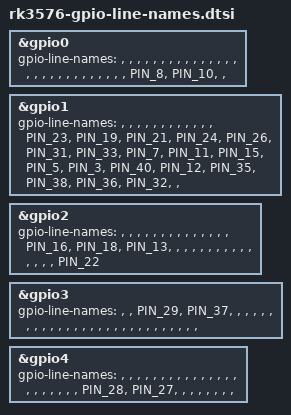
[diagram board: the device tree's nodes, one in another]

&gpio0 {
	gpio-line-names =
		/* GPIO0_A0-A3 */
		"", "", "", "",
		/* GPIO0_A4-A7 */
		"", "", "", "",

		/* GPIO0_B0-B3 */
		"", "", "", "",
		/* GPIO0_B4-B7 */
		"", "", "", "",

		/* GPIO0_C0-C3 */
		"", "", "", "",
		/* GPIO0_C4-C7 */
		"", "", "", "",

		/* GPIO0_D0-D3 */
		"", "", "", "",
		/* GPIO0_D4-D7 */
		"PIN_8", "PIN_10", "", "";
};

&gpio1 {
	gpio-line-names =
		/* GPIO1_A0-A3 */
		"", "", "", "",
		/* GPIO1_A4-A7 */
		"", "", "", "",

		/* GPIO1_B0-B3 */
		"", "", "", "",
		/* GPIO1_B4-B7 */
		"PIN_23", "PIN_19", "PIN_21", "PIN_24",

		/* GPIO1_C0-C3 */
		"PIN_26", "PIN_31", "PIN_33", "PIN_7",
		/* GPIO1_C4-C7 */
		"PIN_11", "PIN_15", "PIN_5", "PIN_3",

		/* GPIO1_D0-D3 */
		"PIN_40", "PIN_12", "PIN_35", "PIN_38",
		/* GPIO1_D4-D7 */
		"PIN_36", "PIN_32", "", "";
};

&gpio2 {
	gpio-line-names =
		/* GPIO2_A0-A3 */
		"", "", "", "",
		/* GPIO2_A4-A7 */
		"", "", "", "",

		/* GPIO2_B0-B3 */
		"", "", "", "",
		/* GPIO2_B4-B7 */
		"", "", "PIN_16", "PIN_18",

		/* GPIO2_C0-C3 */
		"PIN_13", "", "", "",
		/* GPIO2_C4-C7 */
		"", "", "", "",

		/* GPIO2_D0-D3 */
		"", "", "", "",
		/* GPIO2_D4-D7 */
		"", "", "", "PIN_22";
};

&gpio3 {
	gpio-line-names =
		/* GPIO3_A0-A3 */
		"", "", "PIN_29", "PIN_37",
		/* GPIO3_A4-A7 */
		"", "", "", "",

		/* GPIO3_B0-B3 */
		"", "", "", "",
		/* GPIO3_B4-B7 */
		"", "", "", "",

		/* GPIO3_C0-C3 */
		"", "", "", "",
		/* GPIO3_C4-C7 */
		"", "", "", "",

		/* GPIO3_D0-D3 */
		"", "", "", "",
		/* GPIO3_D4-D7 */
		"", "", "", "";
};

&gpio4 {
	gpio-line-names =
		/* GPIO4_A0-A3 */
		"", "", "", "",
		/* GPIO4_A4-A7 */
		"", "", "", "",

		/* GPIO4_B0-B3 */
		"", "", "", "",
		/* GPIO4_B4-B7 */
		"", "", "", "",

		/* GPIO4_C0-C3 */
		"", "", "", "",
		/* GPIO4_C4-C7 */
		"", "", "PIN_28", "PIN_27",

		/* GPIO4_D0-D3 */
		"", "", "", "",
		/* GPIO4_D4-D7 */
		"", "", "", "";
};

